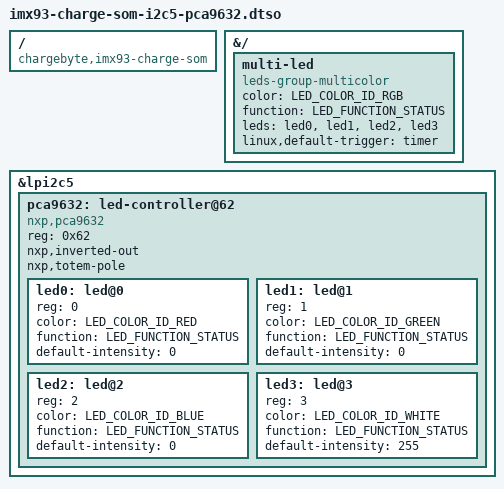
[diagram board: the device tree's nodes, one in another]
// SPDX-License-Identifier: GPL-2.0
/*
 * Copyright (C) 2026 chargebyte GmbH
 * Author: Stefan Wahren <stefan.wahren@chargebyte.com>
 */

#include <dt-bindings/leds/common.h>

/dts-v1/;
/plugin/;

/ {
	compatible = "chargebyte,imx93-charge-som";
};

&{/} {
	multi-led {
		compatible = "leds-group-multicolor";
		color = <LED_COLOR_ID_RGB>;
		function = LED_FUNCTION_STATUS;
		leds = <&led0>, <&led1>, <&led2>, <&led3>;
		linux,default-trigger = "timer";
	};
};

&lpi2c5 {
	#address-cells = <1>;
	#size-cells = <0>;

	pca9632: led-controller@62 {
		compatible = "nxp,pca9632";
		reg = <0x62>;
		#address-cells = <1>;
		#size-cells = <0>;
		nxp,inverted-out;
		nxp,totem-pole;

		led0: led@0 {
			reg = <0>;
			color = <LED_COLOR_ID_RED>;
			function = LED_FUNCTION_STATUS;
			default-intensity = <0>;
		};

		led1: led@1 {
			reg = <1>;
			color = <LED_COLOR_ID_GREEN>;
			function = LED_FUNCTION_STATUS;
			default-intensity = <0>;
		};

		led2: led@2 {
			reg = <2>;
			color = <LED_COLOR_ID_BLUE>;
			function = LED_FUNCTION_STATUS;
			default-intensity = <0>;
		};

		led3: led@3 {
			reg = <3>;
			color = <LED_COLOR_ID_WHITE>;
			function = LED_FUNCTION_STATUS;
			default-intensity = <255>;
		};
	};
};
